# PY32F030xx register map
Vendor: Puya; Series: PY32F0; File version: 1.0.0
CPU: CM0+ r0p1, little endian, no MPU, no FPU, 4 interrupt priority bits
Registers are 32-bit, read-write, reset 0x0 unless marked. A register's access mark holds for its fields unless they carry their own. Offsets are from the block's base; [hi:lo] are bit positions.

## USART1 — Universal synchronous asynchronous receiver transmitter
Base 0x40013800
Same registers: USART2 0x40004400
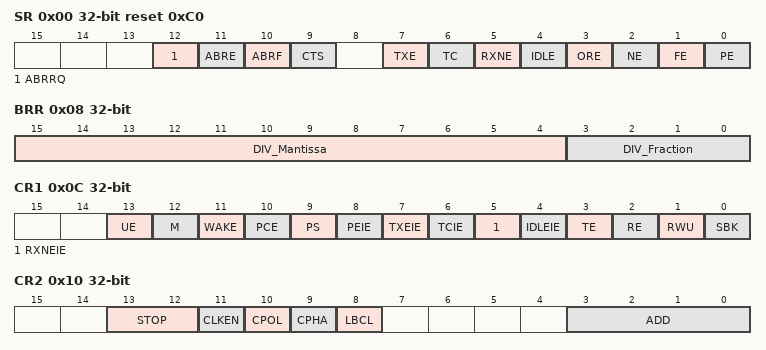
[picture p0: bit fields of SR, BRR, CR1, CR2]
0x00 SR reset 0xC0 — Status register
  [12] ABRRQ wo — Automate baudrate detection requeset
    1=Request (Reset ABRE flag and request auto baud rate detect for next data frame)
  [11] ABRE ro — Automate baudrate detection error flag
    1=Error (Auto baud rate error flag)
  [10] ABRF ro — Automate baudrate detection flag
    1=Detected (Auto baud rate flag)
  [9] CTS — CTS flag
    on read: 0=NotChange (CTS line not change); 1=Toggle (CTS line toggle) | on write: 0=Clear CTS flag
  [7] TXE ro — Transmit data register empty
    0=NotEmpty (Data not transfer to shift register); 1=Empty (Data transferred to shift register)
  [6] TC — Transmission complete
    on read: 0=NotComplete (Data transmit not complete); 1=Complete (Data transmit complete) | on write: 0=Clear TC flag
  [5] RXNE — Read data register not empty
    on read: 0=Empty (No data recived); 1=NotEmpty (Received data) | on write: 0=Clear RXNE flag
  [4] IDLE ro — IDLE line detected
    0=Busy (Idle line not detected); 1=Idle line detected
  [3] ORE ro — Overrun error
  [2] NE ro — Noise error flag
  [1] FE ro — Framing error
  [0] PE ro — Parity error
0x04 DR — Data register
  [8:0] DR — Data value
0x04 DR8 8-bit (alternate view of DR) — Direct 8-bit access to data register
  [7:0] DR — Data register
0x08 BRR — Baud rate register
  [15:4] DIV_Mantissa — mantissa of USARTDIV
  [3:0] DIV_Fraction — fraction of USARTDIV
0x0C CR1 — Control register 1
  [13] UE — USART enable
    0=Disabled (USART prescaler and outputs disabled); 1=Enabled (USART enabled)
  [12] M — Word length
    0=8 data bits; 1=9 data bits
  [11] WAKE — Wakeup method
    0=IdleLine (USART wakeup on idle line); 1=AddressMark (USART wakeup on address mark)
  [10] PCE — Parity control enable
    0=Disabled (Parity control disabled); 1=Enabled (Parity control enabled)
  [9] PS — Parity selection
    0=Even parity; 1=Odd (Odd parity)
  [8] PEIE — PE interrupt enable
    0=Disabled (PE interrupt disabled); 1=Enabled (PE interrupt enabled)
  [7] TXEIE — TXE interrupt enable
    0=Disabled (TXE interrupt disabled); 1=Enabled (TXE interrupt enabled)
  [6] TCIE — Transmission complete interrupt enable
    0=Disabled (TC interrupt disabled); 1=Enabled (TC interrupt enabled)
  [5] RXNEIE — RXNE interrupt enable
    0=Disabled (RXNE interrupt disabled); 1=Enabled (RXNE interrupt enabled)
  [4] IDLEIE — IDLE interrupt enable
    0=Disabled (IDLE interrupt disabled); 1=Enabled (IDLE interrupt enabled)
  [3] TE — Transmitter enable
    0=Disabled (Transmitter disabled); 1=Enabled (Transmitter enabled)
  [2] RE — Receiver enable
    0=Disabled (Receiver disabled); 1=Enabled (Receiver enabled)
  [1] RWU — Receiver wakeup
    0=Active (Receiver in active mode); 1=Mute (Receiver in mute mode)
  [0] SBK — Send break
    0=No break character is transmitted; 1=Break character transmitted
0x10 CR2 — Control register 2
  [13:12] STOP — STOP bits
    0=1 stop bit; 1=2 stop bits
  [11] CLKEN — Clock enable
    0=Disabled (CK pin disabled); 1=Enabled (CK pin enabled)
  [10] CPOL — Clock polarity
    0=Low (Steady low value on CK pin outside transmission window); 1=High (Steady high value on CK pin outside transmission window)
  [9] CPHA — Clock phase
    0=First (The first clock transition is the first data capture edge); 1=Second (The second clock transition is the first data capture edge)
  [8] LBCL — Last bit clock pulse
    0=NotOutput (The clock pulse of the last data bit is not output to the CK pin); 1=Output (The clock pulse of the last data bit is output to the CK pin)
  [3:0] ADD — Address of the USART node
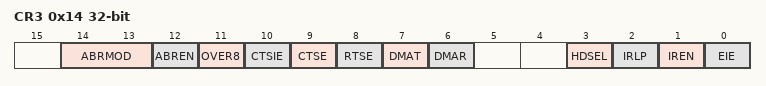
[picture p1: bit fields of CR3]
0x14 CR3 — Control register 3
  [14:13] ABRMOD — Auto baudrate mode
    0=Start (Measurement of the start bit is used to detect the baud rate); 1=Edge (Falling edge to falling edge measurement)
  [12] ABREN — Auto baudrate enable
    0=Disabled (Auto baud rate detection is disabled); 1=Enabled (Auto baud rate detection is enabled)
  [11] OVER8 — Oversampling mode
    0=Oversampling16 (Oversampling by 16); 1=Oversampling8 (Oversampling by 8)
  [10] CTSIE — CTS interrupt enable
    0=Disabled (CTS interrupt disabled); 1=Enabled (CTS interrupt enabled)
  [9] CTSE — CTS enable
    0=Disabled (CTS hardware flow control disabled); 1=Enabled (CTS hardware flow control enabled)
  [8] RTSE — RTS enable
    0=Disabled (RTS hardware flow control disabled); 1=Enabled (RTS hardware flow control enabled)
  [7] DMAT — DMA enable transmitter
    0=Disabled (DMA mode is disabled for transmission); 1=Enabled (DMA mode is enabled for transmission)
  [6] DMAR — DMA enable receiver
    0=Disabled (DMA mode is disabled for reception); 1=Enabled (DMA mode is enabled for reception)
  [3] HDSEL — Half-duplex selection
    0=FullDuplex (Half duplex mode is not selected); 1=Half duplex mode is selected
  [2] IRLP — IrDA low-power
    0=Normal mode; 1=Low-power mode
  [1] IREN — IrDA mode enable
    0=Disabled (IrDA disabled); 1=Enabled (IrDA enabled)
  [0] EIE — Error interrupt enable
    0=Disabled (Error interrupt disabled); 1=Enabled (Error interrupt enabled)
